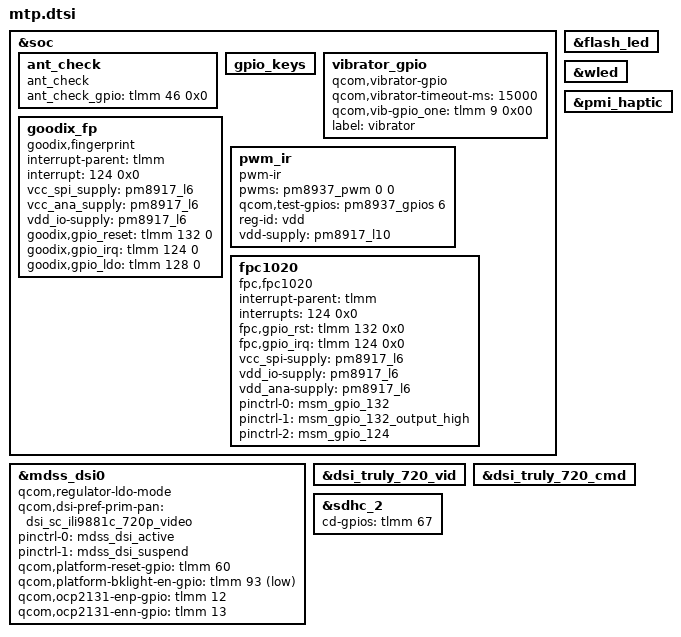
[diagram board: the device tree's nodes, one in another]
&soc {
	ant_check {
		compatible = "ant_check";
		ant_check_gpio = <&tlmm 46 0x0>;
	};

	gpio_keys {
		/delete-node/ camera_focus;
		/delete-node/ camera_snapshot;
	};

	/delete-node/ hbtp;

	vibrator_gpio {
		compatible = "qcom,vibrator-gpio";
		qcom,vibrator-timeout-ms = <15000>;
		qcom,vib-gpio_one = <&tlmm 9 0x00>;
		label = "vibrator";
	};

	goodix_fp{
		compatible = "goodix,fingerprint";
		interrupt-parent = <&tlmm>;
		interrupt = <124 0x0>;
		vcc_spi_supply = <&pm8917_l6>;
		vcc_ana_supply = <&pm8917_l6>;
		vdd_io-supply = <&pm8917_l6>;
		goodix,gpio_reset = <&tlmm 132 0>;
		goodix,gpio_irq = <&tlmm 124 0>;
		goodix,gpio_ldo = <&tlmm 128 0>;
	};

	pwm_ir {
		compatible = "pwm-ir";
		pwms = <&pm8937_pwm 0 0>;
		qcom,test-gpios = <&pm8937_gpios 6 0>;
		reg-id = "vdd";
		vdd-supply = <&pm8917_l10>;
	};

	fpc1020 {
		status = "ok";
		compatible = "fpc,fpc1020";
		interrupt-parent = <&tlmm>;
		interrupts = <124 0x0>;
		fpc,gpio_rst    = <&tlmm 132 0x0>;
		fpc,gpio_irq    = <&tlmm 124 0x0>;
		vcc_spi-supply  = <&pm8917_l6>;
		vdd_io-supply   = <&pm8917_l6>;
		vdd_ana-supply  = <&pm8917_l6>;

		pinctrl-names = "fpc1020_reset_reset",
			"fpc1020_reset_active",
			"fpc1020_irq_active";

		pinctrl-0 = <&msm_gpio_132>;
		pinctrl-1 = <&msm_gpio_132_output_high>;
		pinctrl-2 = <&msm_gpio_124>;
	};
};

&flash_led {
	/delete-property/ compatible;
	/delete-property/ reg;
	/delete-property/ pinctrl-names;
	/delete-property/ pinctrl-0;
	/delete-property/ pinctrl-1;
	/delete-property/ qcom,follow-otst2-rb-disabled;
};

&wled {
	/delete-property/ qcom,cons-sync-write-delay-us;
};

&pmi_haptic{
	/delete-property/ qcom,actuator-type;
	/delete-property/ qcom,wave-play-rate-us;
	/delete-property/ qcom,lra-auto-res-mode;
	/delete-property/ qcom,lra-high-z;
	/delete-property/ qcom,lra-res-cal-period;
};

&mdss_dsi0 {
	/delete-property/ qcom,platform-te-gpio;
};

&dsi_truly_720_vid {
	/delete-property/ qcom,panel-supply-entries;
	/delete-property/ qcom,mdss-dsi-pan-enable-dynamic-fps;
	/delete-property/ qcom,mdss-dsi-pan-fps-update;
};

&dsi_truly_720_cmd {
	/delete-property/ qcom,panel-supply-entries;
	/delete-property/ qcom,ulps-enabled;
	/delete-property/ qcom,partial-update-enabled;
	/delete-property/ qcom,panel-roi-alignment;
};

&mdss_dsi0 {
	qcom,regulator-ldo-mode;
	qcom,dsi-pref-prim-pan = <&dsi_sc_ili9881c_720p_video>;
	pinctrl-names = "mdss_default", "mdss_sleep";
	pinctrl-0 = <&mdss_dsi_active>;
	pinctrl-1 = <&mdss_dsi_suspend>;

	qcom,platform-reset-gpio = <&tlmm 60 0>;
	qcom,platform-bklight-en-gpio = <&tlmm 93 1>;
	qcom,ocp2131-enp-gpio = <&tlmm 12 0>;
	qcom,ocp2131-enn-gpio = <&tlmm 13 0>;
};

&sdhc_2 {
	cd-gpios = <&tlmm 67 0x0>;
};
